# XMC4500 register map
Vendor: Infineon; File version: 1.2.0 (Reference Manual v1.2)
CPU: CM4 r2p0, little endian, MPU, FPU, 6 interrupt priority bits
Registers are 32-bit, read-write, reset 0x0 unless marked. A register's access mark holds for its fields unless they carry their own. Offsets are from the block's base; [hi:lo] are bit positions; {n}, {i} and the like mark numbered series.

## PORT14
Base 0x48028E00
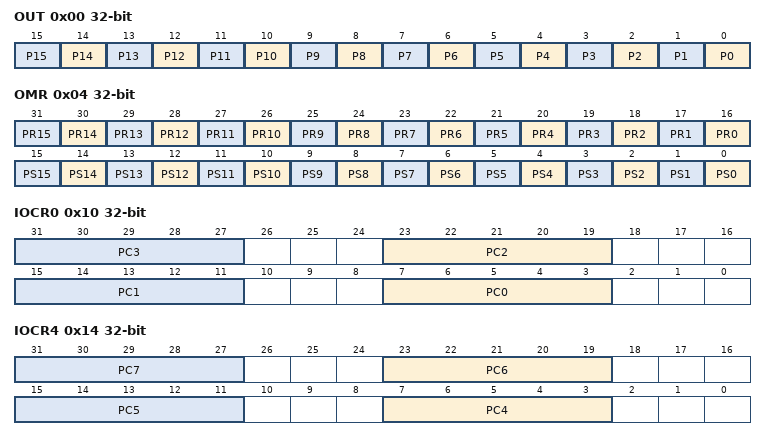
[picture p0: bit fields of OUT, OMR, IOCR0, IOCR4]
0x00 OUT — Port 14 Output Register
  [all] fields
    0=The output level of Pn.x is 0; 1=The output level of Pn.x is 1
  [n] P{n} (n=0..15) — Port n Output Bit {n}
0x04 OMR wo — Port 14 Output Modification Register
  [n+16] PR{n} (n=0..15) — Port n Reset Bit {n}
  [n] PS{n} (n=0..15) — Port n Set Bit {n}
0x10 IOCR0 — Port 14 Input/Output Control Register 0
  [8n+7:8n+3] PC{n} (n=0..3) — Port Control for Port n Pin 0 to 3
0x14 IOCR4 — Port 14 Input/Output Control Register 4
  [8n-25:8n-29] PC{n} (n=4..7) — Port Control for Port n Pin 4 to 7
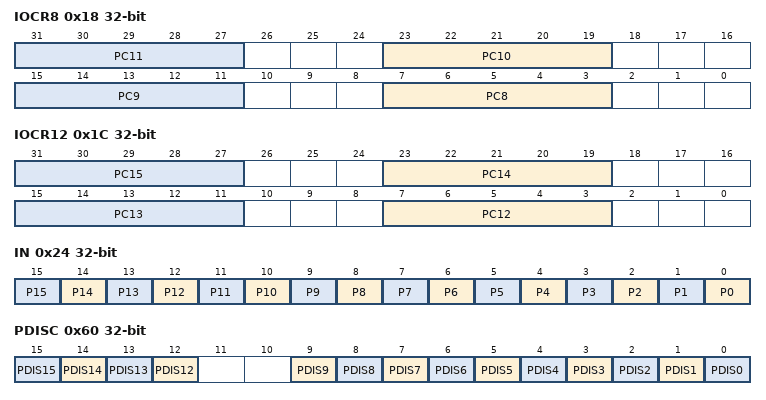
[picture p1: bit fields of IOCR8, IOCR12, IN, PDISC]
0x18 IOCR8 — Port 14 Input/Output Control Register 8
  [8n-57:8n-61] PC{n} (n=8..11) — Port Control for Port n Pin 8 to 11
0x1C IOCR12 — Port 14 Input/Output Control Register 12
  [8n-89:8n-93] PC{n} (n=12..15) — Port Control for Port n Pin 12 to 15
0x24 IN ro (reset mask 0xFFFF0000) — Port 14 Input Register
  [all] fields
    0=The input level of Pn.x is 0; 1=The input level of Pn.x is 1
  [n] P{n} (n=0..15) — Port n Input Bit {n}
0x60 PDISC (reset mask 0xFFFF0000) — Port 14 Pin Function Decision Control Register
  [n] PDIS{n} (n=12..15) — Pad Disable for Port 14 Pin {n}
    0=Pad is enabled, digital input selected; 1=Pad is disabled, ADC 1 analog input {n-8} selected
  [9] PDIS9 — Pad Disable for Port 14 Pin 9
    0=Pad is enabled, digital input selected; 1=Pad is disabled, ADC 1 analog input 1 and ADC 2 analog input 5 and DAC output 1 selected
  [8] PDIS8 — Pad Disable for Port 14 Pin 8
    0=Pad is enabled, digital input selected; 1=Pad is disabled, ADC 1 analog input 0 and ADC 2 analog input 4 and DAC output 0 selected
  [7] PDIS7 — Pad Disable for Port 14 Pin 7
    0=Pad is enabled, digital input selected; 1=Pad is disabled, ADC0 analog input 7 selected
  [6] PDIS6 — Pad Disable for Port 14 Pin 6
    0=Pad is enabled, digital input selected; 1=Pad is disabled, ADC 0 analog input 6 selected
  [5] PDIS5 — Pad Disable for Port 14 Pin 5
    0=Pad is enabled, digital input selected; 1=Pad is disabled, ADC 0 analog input 5 and ADC 2 analog input 1 selected
  [4] PDIS4 — Pad Disable for Port 14 Pin 4
    0=Pad is enabled, digital input selected; 1=Pad is disabled, ADC 0 analog input 4 and ADC 2 analog input 0 and DAC Reference selected
  [3] PDIS3 — Pad Disable for Port 14 Pin 3
    0=Pad is enabled, digital input selected; 1=Pad is disabled, ADC 0 and ADC 1 analog input 3 selected
  [2] PDIS2 — Pad Disable for Port 14 Pin 2
    0=Pad is enabled, digital input selected; 1=Pad is disabled, ADC 0 and ADC 1 analog input 2 selected
  [1] PDIS1 — Pad Disable for Port 14 Pin 1
    0=Pad is enabled, digital input selected; 1=Pad is disabled, ADC 0 analog input 1 selected
  [0] PDIS0 — Pad Disable for Port 14 Pin 0
    0=Pad is enabled, digital input selected; 1=Pad is disabled, ADC 0 analog input 0 selected
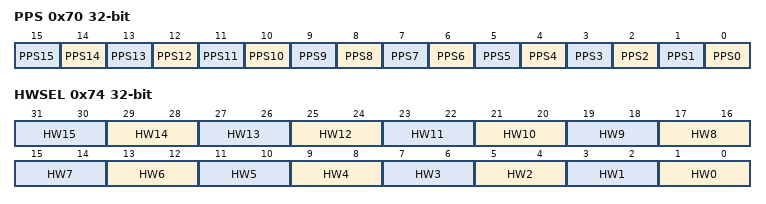
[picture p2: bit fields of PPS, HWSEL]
0x70 PPS — Port 14 Pin Power Save Register
  [all] fields
    0=Pin Power Save of Pn.x is disabled; 1=Pin Power Save of Pn.x is enabled
  [n] PPS{n} (n=0..15) — Port n Pin Power Save Bit {n}
0x74 HWSEL — Port 14 Pin Hardware Select Register
  [all] fields
    0=Software control only; 1=HW0 control path can override the software configuration; 2=HW1 control path can override the software configuration
  [2n+1:2n] HW{n} (n=0..15) — Port n Pin Hardware Select Bit {n}

## PORT15
Base 0x48028F00
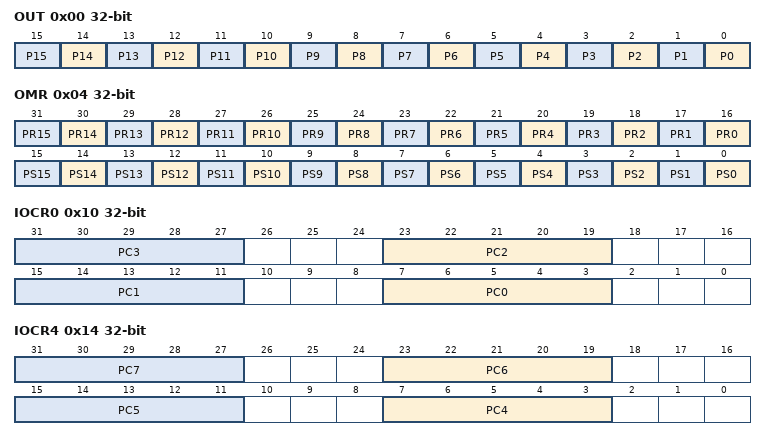
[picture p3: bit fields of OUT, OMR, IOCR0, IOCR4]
0x00 OUT — Port 15 Output Register
  [all] fields
    0=The output level of Pn.x is 0; 1=The output level of Pn.x is 1
  [n] P{n} (n=0..15) — Port n Output Bit {n}
0x04 OMR wo — Port 15 Output Modification Register
  [n+16] PR{n} (n=0..15) — Port n Reset Bit {n}
  [n] PS{n} (n=0..15) — Port n Set Bit {n}
0x10 IOCR0 — Port 15 Input/Output Control Register 0
  [8n+7:8n+3] PC{n} (n=0..3) — Port Control for Port n Pin 0 to 3
0x14 IOCR4 — Port 15 Input/Output Control Register 4
  [8n-25:8n-29] PC{n} (n=4..7) — Port Control for Port n Pin 4 to 7
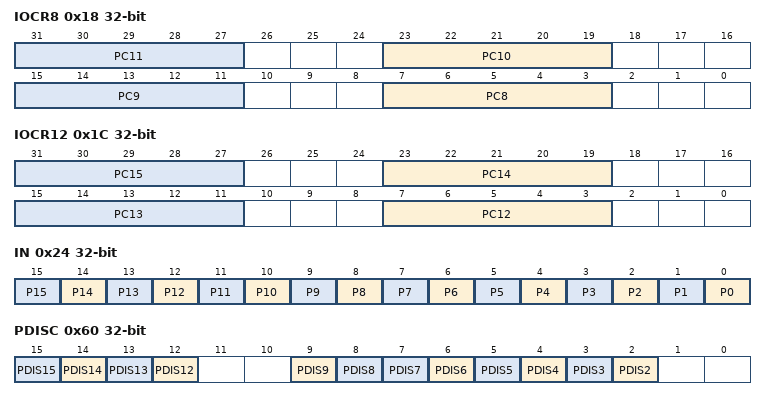
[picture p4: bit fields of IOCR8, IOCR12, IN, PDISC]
0x18 IOCR8 — Port 15 Input/Output Control Register 8
  [8n-57:8n-61] PC{n} (n=8..11) — Port Control for Port n Pin 8 to 11
0x1C IOCR12 — Port 15 Input/Output Control Register 12
  [8n-89:8n-93] PC{n} (n=12..15) — Port Control for Port n Pin 12 to 15
0x24 IN ro (reset mask 0xFFFF0000) — Port 15 Input Register
  [all] fields
    0=The input level of Pn.x is 0; 1=The input level of Pn.x is 1
  [n] P{n} (n=0..15) — Port n Input Bit {n}
0x60 PDISC (reset mask 0xFFFF0000) — Port 15 Pin Function Decision Control Register
  [n] PDIS{n} (n=12..15) — Pad Disable for Port 15 Pin {n}
    0=Pad is enabled, digital input selected; 1=Pad is disabled, ADC 3 analog input {n-8}
  [9] PDIS9 — Pad Disable for Port 15 Pin 9
    0=Pad is enabled, digital input selected; 1=Pad is disabled, ADC 3 analog input 1
  [8] PDIS8 — Pad Disable for Port 15 Pin 8
    0=Pad is enabled, digital input selected; 1=Pad is disabled, ADC 3 analog input 0
  [n] PDIS{n} (n=2..7) — Pad Disable for Port 15 Pin {n}
    0=Pad is enabled, digital input selected; 1=Pad is disabled, ADC 2 analog input {n}
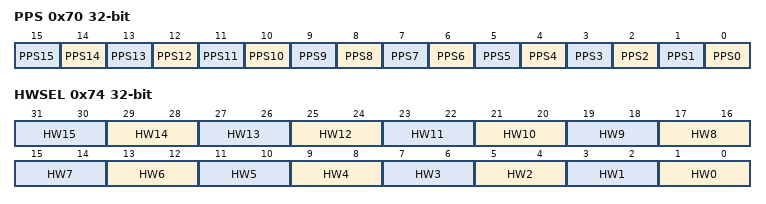
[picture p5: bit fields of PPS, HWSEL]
0x70 PPS — Port 15 Pin Power Save Register
  [all] fields
    0=Pin Power Save of Pn.x is disabled; 1=Pin Power Save of Pn.x is enabled
  [n] PPS{n} (n=0..15) — Port n Pin Power Save Bit {n}
0x74 HWSEL — Port 15 Pin Hardware Select Register
  [all] fields
    0=Software control only; 1=HW0 control path can override the software configuration; 2=HW1 control path can override the software configuration
  [2n+1:2n] HW{n} (n=0..15) — Port n Pin Hardware Select Bit {n}
